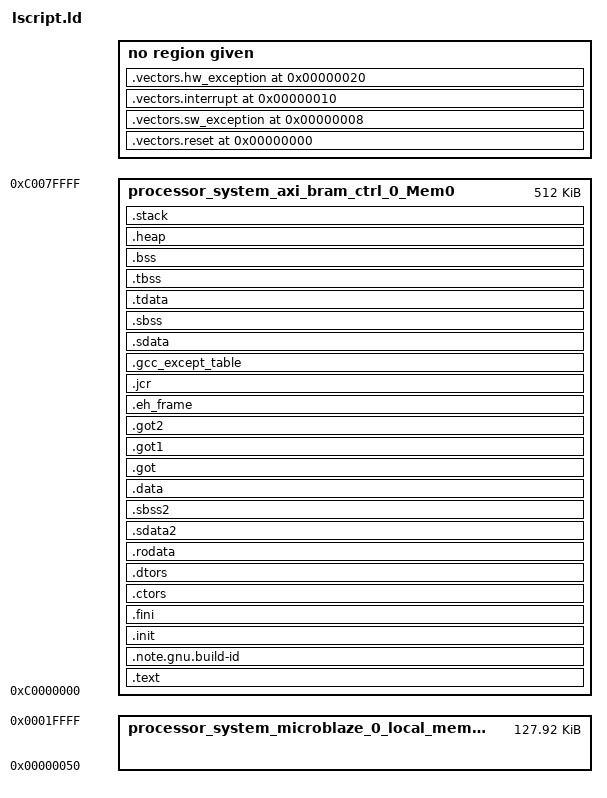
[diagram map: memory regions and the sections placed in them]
/*******************************************************************/
/*                                                                 */
/* This file is automatically generated by linker script generator.*/
/*                                                                 */
/* Version: 2018.3                                                 */
/*                                                                 */
/* Copyright (c) 2010-2022 Xilinx, Inc.  All rights reserved.      */
/* Copyright 2023-2024 Advanced Micro Devices, Inc. All Rights Reserved */
/*                                                                 */
/* Description : MicroBlaze Linker Script                           */
/*                                                                 */
/*******************************************************************/

_STACK_SIZE = DEFINED(_STACK_SIZE) ? _STACK_SIZE : 0x1000;
_HEAP_SIZE = DEFINED(_HEAP_SIZE) ? _HEAP_SIZE : 0x1000;

/* Define Memories in the system */

MEMORY
{
   processor_system_microblaze_0_local_memory_ilmb_bram_if_cntlr_Mem_processor_system_microblaze_0_local_memory_dlmb_bram_if_cntlr_Mem : ORIGIN = 0x50, LENGTH = 0x1FFB0
   processor_system_axi_bram_ctrl_0_Mem0 : ORIGIN = 0xC0000000, LENGTH = 0x80000
}

/* Specify the default entry point to the program */

ENTRY(_start)

/* Define the sections, and where they are mapped in memory */

SECTIONS
{
.vectors.reset 0x0 : {
   KEEP (*(.vectors.reset))
}

.vectors.sw_exception 0x8 : {
   KEEP (*(.vectors.sw_exception))
}

.vectors.interrupt 0x10 : {
   KEEP (*(.vectors.interrupt))
}

.vectors.hw_exception 0x20 : {
   KEEP (*(.vectors.hw_exception))
}

.text : {
   *(.text)
   *(.text.*)
   *(.gnu.linkonce.t.*)
} > processor_system_axi_bram_ctrl_0_Mem0

.note.gnu.build-id : {
   KEEP (*(.note.gnu.build-id))
} > processor_system_axi_bram_ctrl_0_Mem0

.init : {
   KEEP (*(.init))
} > processor_system_axi_bram_ctrl_0_Mem0

.fini : {
   KEEP (*(.fini))
} > processor_system_axi_bram_ctrl_0_Mem0

.ctors : {
   __CTOR_LIST__ = .;
   ___CTORS_LIST___ = .;
   KEEP (*crtbegin.o(.ctors))
   KEEP (*(EXCLUDE_FILE(*crtend.o) .ctors))
   KEEP (*(SORT(.ctors.*)))
   KEEP (*(.ctors))
   __CTOR_END__ = .;
   ___CTORS_END___ = .;
} > processor_system_axi_bram_ctrl_0_Mem0

.dtors : {
   __DTOR_LIST__ = .;
   ___DTORS_LIST___ = .;
   KEEP (*crtbegin.o(.dtors))
   KEEP (*(EXCLUDE_FILE(*crtend.o) .dtors))
   KEEP (*(SORT(.dtors.*)))
   KEEP (*(.dtors))
   PROVIDE(__DTOR_END__ = .);
   PROVIDE(___DTORS_END___ = .);
} > processor_system_axi_bram_ctrl_0_Mem0

.rodata : {
   __rodata_start = .;
   *(.rodata)
   *(.rodata.*)
   *(.gnu.linkonce.r.*)
   __rodata_end = .;
} > processor_system_axi_bram_ctrl_0_Mem0

.sdata2 : {
   . = ALIGN(8);
   __sdata2_start = .;
   *(.sdata2)
   *(.sdata2.*)
   *(.gnu.linkonce.s2.*)
   . = ALIGN(8);
   __sdata2_end = .;
} > processor_system_axi_bram_ctrl_0_Mem0

.sbss2 : {
   __sbss2_start = .;
   *(.sbss2)
   *(.sbss2.*)
   *(.gnu.linkonce.sb2.*)
   __sbss2_end = .;
} > processor_system_axi_bram_ctrl_0_Mem0

.data : {
   . = ALIGN(4);
   __data_start = .;
   *(.data)
   *(.data.*)
   *(.gnu.linkonce.d.*)
   __data_end = .;
} > processor_system_axi_bram_ctrl_0_Mem0

.got : {
   *(.got)
} > processor_system_axi_bram_ctrl_0_Mem0

.got1 : {
   *(.got1)
} > processor_system_axi_bram_ctrl_0_Mem0

.got2 : {
   *(.got2)
} > processor_system_axi_bram_ctrl_0_Mem0

.eh_frame : {
   *(.eh_frame)
} > processor_system_axi_bram_ctrl_0_Mem0

.jcr : {
   *(.jcr)
} > processor_system_axi_bram_ctrl_0_Mem0

.gcc_except_table : {
   *(.gcc_except_table)
} > processor_system_axi_bram_ctrl_0_Mem0

.sdata : {
   . = ALIGN(8);
   __sdata_start = .;
   *(.sdata)
   *(.sdata.*)
   *(.gnu.linkonce.s.*)
   __sdata_end = .;
} > processor_system_axi_bram_ctrl_0_Mem0

.sbss (NOLOAD) : {
   . = ALIGN(4);
   __sbss_start = .;
   *(.sbss)
   *(.sbss.*)
   *(.gnu.linkonce.sb.*)
   . = ALIGN(8);
   __sbss_end = .;
} > processor_system_axi_bram_ctrl_0_Mem0

.tdata : {
   __tdata_start = .;
   *(.tdata)
   *(.tdata.*)
   *(.gnu.linkonce.td.*)
   __tdata_end = .;
} > processor_system_axi_bram_ctrl_0_Mem0

.tbss : {
   __tbss_start = .;
   *(.tbss)
   *(.tbss.*)
   *(.gnu.linkonce.tb.*)
   __tbss_end = .;
} > processor_system_axi_bram_ctrl_0_Mem0

.bss (NOLOAD) : {
   . = ALIGN(4);
   __bss_start = .;
   *(.bss)
   *(.bss.*)
   *(.gnu.linkonce.b.*)
   *(COMMON)
   . = ALIGN(4);
   __bss_end = .;
} > processor_system_axi_bram_ctrl_0_Mem0

_SDA_BASE_ = __sdata_start + ((__sbss_end - __sdata_start) / 2 );

_SDA2_BASE_ = __sdata2_start + ((__sbss2_end - __sdata2_start) / 2 );

/* Generate Stack and Heap definitions */

.heap (NOLOAD) : {
   . = ALIGN(8);
   _heap = .;
   _heap_start = .;
   . += _HEAP_SIZE;
   _heap_end = .;
} > processor_system_axi_bram_ctrl_0_Mem0

.stack (NOLOAD) : {
   _stack_end = .;
   . += _STACK_SIZE;
   . = ALIGN(8);
   _stack = .;
   __stack = _stack;
} > processor_system_axi_bram_ctrl_0_Mem0

_end = .;
}
